# Espressif register map
File version: 1.0
CPU: Xtensa LX6 1, little endian, no MPU, FPU, 3 interrupt priority bits
Registers are 32-bit, access not given, reset 0x0 unless marked. A register's access mark holds for its fields unless they carry their own. Offsets are from the block's base; [hi:lo] are bit positions; {n}, {i} and the like mark numbered series.

## EFUSE
Base 0x3FF5A000
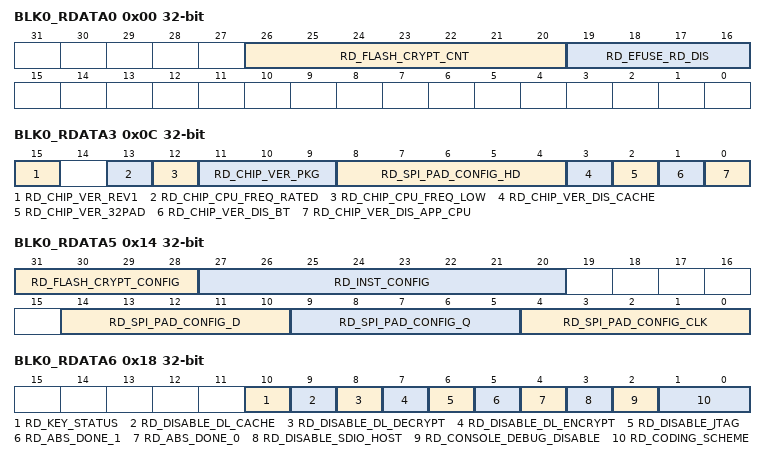
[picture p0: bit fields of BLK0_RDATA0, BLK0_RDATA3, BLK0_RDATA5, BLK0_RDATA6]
0x00 BLK0_RDATA0 — EFUSE_BLK0_RDATA0
  [26:20] RD_FLASH_CRYPT_CNT, [19:16] RD_EFUSE_RD_DIS
0x04 BLK0_RDATA1 — EFUSE_BLK0_RDATA1
  [31:0] RD_WIFI_MAC_CRC_LOW
0x08 BLK0_RDATA2 — EFUSE_BLK0_RDATA2
  [23:0] RD_WIFI_MAC_CRC_HIGH
0x0C BLK0_RDATA3 — EFUSE_BLK0_RDATA3
  [15] RD_CHIP_VER_REV1, [13] RD_CHIP_CPU_FREQ_RATED, [12] RD_CHIP_CPU_FREQ_LOW, [11:9] RD_CHIP_VER_PKG, [8:4] RD_SPI_PAD_CONFIG_HD, [3] RD_CHIP_VER_DIS_CACHE, [2] RD_CHIP_VER_32PAD, [1] RD_CHIP_VER_DIS_BT, [0] RD_CHIP_VER_DIS_APP_CPU
0x10 BLK0_RDATA4 — EFUSE_BLK0_RDATA4
  [16] RD_SDIO_FORCE, [15] RD_SDIO_TIEH, [14] RD_XPD_SDIO_REG, [13:12] RD_SDIO_DREFL, [11:10] RD_SDIO_DREFM, [12:8] RD_ADC_VREF, [9:8] RD_SDIO_DREFH, [7:0] RD_CK8M_FREQ
0x14 BLK0_RDATA5 — EFUSE_BLK0_RDATA5
  [31:28] RD_FLASH_CRYPT_CONFIG, [27:20] RD_INST_CONFIG, [14:10] RD_SPI_PAD_CONFIG_D, [9:5] RD_SPI_PAD_CONFIG_Q, [4:0] RD_SPI_PAD_CONFIG_CLK
0x18 BLK0_RDATA6 — EFUSE_BLK0_RDATA6
  [10] RD_KEY_STATUS, [9] RD_DISABLE_DL_CACHE, [8] RD_DISABLE_DL_DECRYPT, [7] RD_DISABLE_DL_ENCRYPT, [6] RD_DISABLE_JTAG, [5] RD_ABS_DONE_1, [4] RD_ABS_DONE_0, [3] RD_DISABLE_SDIO_HOST, [2] RD_CONSOLE_DEBUG_DISABLE, [1:0] RD_CODING_SCHEME
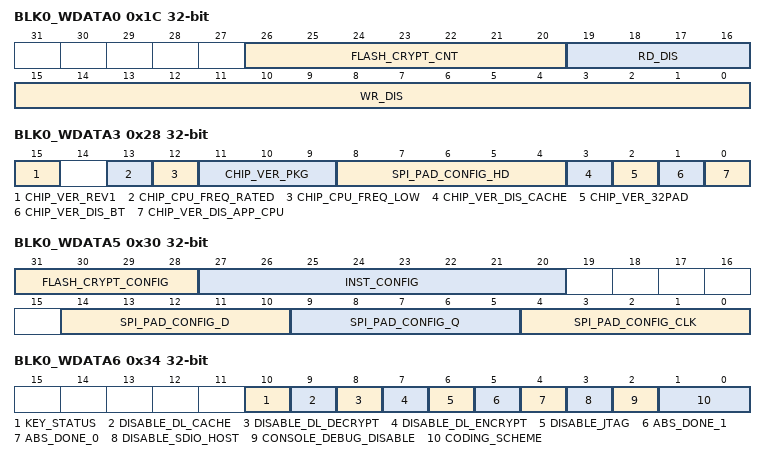
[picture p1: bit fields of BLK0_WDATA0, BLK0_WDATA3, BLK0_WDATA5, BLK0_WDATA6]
0x1C BLK0_WDATA0 — EFUSE_BLK0_WDATA0
  [26:20] FLASH_CRYPT_CNT, [19:16] RD_DIS, [15:0] WR_DIS
0x20 BLK0_WDATA1 — EFUSE_BLK0_WDATA1
  [31:0] WIFI_MAC_CRC_LOW
0x24 BLK0_WDATA2 — EFUSE_BLK0_WDATA2
  [23:0] WIFI_MAC_CRC_HIGH
0x28 BLK0_WDATA3 — EFUSE_BLK0_WDATA3
  [15] CHIP_VER_REV1, [13] CHIP_CPU_FREQ_RATED, [12] CHIP_CPU_FREQ_LOW, [11:9] CHIP_VER_PKG, [8:4] SPI_PAD_CONFIG_HD, [3] CHIP_VER_DIS_CACHE, [2] CHIP_VER_32PAD, [1] CHIP_VER_DIS_BT, [0] CHIP_VER_DIS_APP_CPU
0x2C BLK0_WDATA4 — EFUSE_BLK0_WDATA4
  [16] SDIO_FORCE, [15] SDIO_TIEH, [14] XPD_SDIO_REG, [13:12] SDIO_DREFL, [11:10] SDIO_DREFM, [12:8] ADC_VREF, [9:8] SDIO_DREFH, [7:0] CK8M_FREQ
0x30 BLK0_WDATA5 — EFUSE_BLK0_WDATA5
  [31:28] FLASH_CRYPT_CONFIG, [27:20] INST_CONFIG, [14:10] SPI_PAD_CONFIG_D, [9:5] SPI_PAD_CONFIG_Q, [4:0] SPI_PAD_CONFIG_CLK
0x34 BLK0_WDATA6 — EFUSE_BLK0_WDATA6
  [10] KEY_STATUS, [9] DISABLE_DL_CACHE, [8] DISABLE_DL_DECRYPT, [7] DISABLE_DL_ENCRYPT, [6] DISABLE_JTAG, [5] ABS_DONE_1, [4] ABS_DONE_0, [3] DISABLE_SDIO_HOST, [2] CONSOLE_DEBUG_DISABLE, [1:0] CODING_SCHEME
{0x38+4i} BLK1_RDATA{i} (i=0..7) — EFUSE_BLK1_RDATA{i}
  [31:0] BLK1_DOUT{i}
{0x58+4i} BLK2_RDATA{i} (i=0..7) — EFUSE_BLK2_RDATA{i}
  [31:0] BLK2_DOUT{i}
{0x78+4i} BLK3_RDATA{i} (i=0..2) — EFUSE_BLK3_RDATA{i}
  [31:0] BLK3_DOUT{i}
0x84 BLK3_RDATA3 — EFUSE_BLK3_RDATA3
  [31:23] RD_ADC2_TP_HIGH, [22:16] RD_ADC2_TP_LOW, [15:7] RD_ADC1_TP_HIGH, [31:0] BLK3_DOUT3, [6:0] RD_ADC1_TP_LOW
{0x78+4i} BLK3_RDATA{i} (i=4..7) — EFUSE_BLK3_RDATA{i}
  [31:0] BLK3_DOUT{i}
{0x98+4i} BLK1_WDATA{i} (i=0..7) — EFUSE_BLK1_WDATA{i}
  [31:0] BLK1_DIN{i}
{0xB8+4i} BLK2_WDATA{i} (i=0..7) — EFUSE_BLK2_WDATA{i}
  [31:0] BLK2_DIN{i}
{0xD8+4i} BLK3_WDATA{i} (i=0..2) — EFUSE_BLK3_WDATA{i}
  [31:0] BLK3_DIN{i}
0xE4 BLK3_WDATA3 — EFUSE_BLK3_WDATA3
  [31:23] ADC2_TP_HIGH, [22:16] ADC2_TP_LOW, [15:7] ADC1_TP_HIGH, [31:0] BLK3_DIN3, [6:0] ADC1_TP_LOW
{0xD8+4i} BLK3_WDATA{i} (i=4..7) — EFUSE_BLK3_WDATA{i}
  [31:0] BLK3_DIN{i}
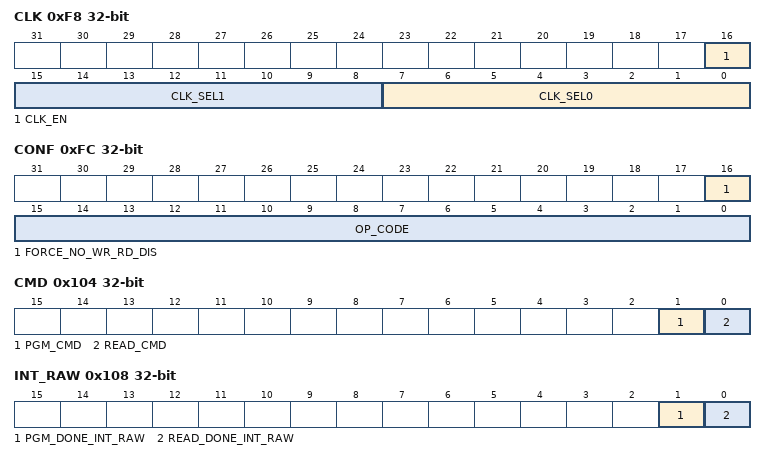
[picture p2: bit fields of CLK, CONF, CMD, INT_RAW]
0xF8 CLK — EFUSE_CLK
  [16] CLK_EN, [15:8] CLK_SEL1, [7:0] CLK_SEL0
0xFC CONF — EFUSE_CONF
  [16] FORCE_NO_WR_RD_DIS, [15:0] OP_CODE
0x100 STATUS — EFUSE_STATUS
  [31:0] DEBUG
0x104 CMD — EFUSE_CMD
  [1] PGM_CMD, [0] READ_CMD
0x108 INT_RAW — EFUSE_INT_RAW
  [1] PGM_DONE_INT_RAW, [0] READ_DONE_INT_RAW
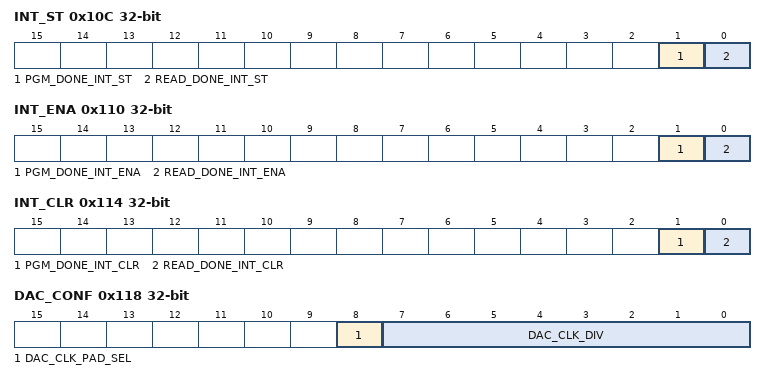
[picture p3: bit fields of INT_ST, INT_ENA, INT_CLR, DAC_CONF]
0x10C INT_ST — EFUSE_INT_ST
  [1] PGM_DONE_INT_ST, [0] READ_DONE_INT_ST
0x110 INT_ENA — EFUSE_INT_ENA
  [1] PGM_DONE_INT_ENA, [0] READ_DONE_INT_ENA
0x114 INT_CLR — EFUSE_INT_CLR
  [1] PGM_DONE_INT_CLR, [0] READ_DONE_INT_CLR
0x118 DAC_CONF — EFUSE_DAC_CONF
  [8] DAC_CLK_PAD_SEL, [7:0] DAC_CLK_DIV
0x11C DEC_STATUS — EFUSE_DEC_STATUS
  [11:0] DEC_WARNINGS
0x1FC DATE — EFUSE_DATE
